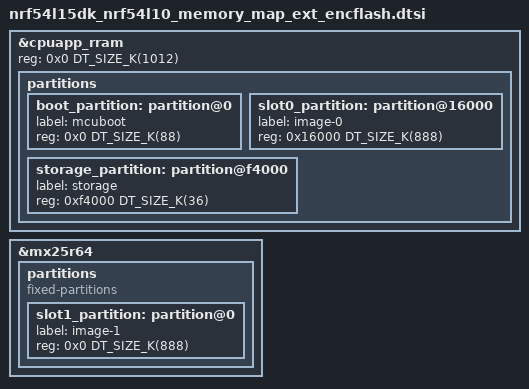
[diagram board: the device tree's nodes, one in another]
/*
 * Copyright (c) 2026 Nordic Semiconductor ASA
 *
 * SPDX-License-Identifier: LicenseRef-Nordic-5-Clause
 */

/delete-node/ &boot_partition;
/delete-node/ &slot0_partition;
/delete-node/ &slot1_partition;
/delete-node/ &storage_partition;

&cpuapp_rram {
	reg = <0x0 DT_SIZE_K(1012)>;

	partitions {
		boot_partition: partition@0 {
			label = "mcuboot";
			reg = <0x0 DT_SIZE_K(88)>;
		};

		slot0_partition: partition@16000 {
			label = "image-0";
			reg = <0x16000 DT_SIZE_K(888)>;
		};

		storage_partition: partition@f4000 {
			label = "storage";
			reg = <0xf4000 DT_SIZE_K(36)>;
		};
	};
};

&mx25r64 {
	partitions {
		compatible = "fixed-partitions";
		#address-cells = <1>;
		#size-cells = <1>;

		slot1_partition: partition@0 {
			label = "image-1";
			reg = <0x0 DT_SIZE_K(888)>;
		};
	};
};
